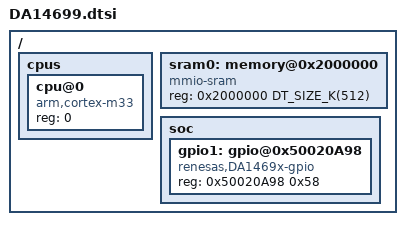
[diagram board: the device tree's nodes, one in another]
#include <dt-bindings/gpio/gpio.h>
#include <mem.h>

// sysclk: system-clock {
// 	compatible = "fixed-clock";
// 	clock-frequency = <25000000>;
// 	#clock-cells = <0>;
// };

/ {

	cpus {
		#address-cells = <1>;
		#size-cells = <0>;

		cpu@0 {
			device_type = "cpu";
			compatible = "arm,cortex-m33";
			reg = <0>;
			#address-cells = <1>;
			#size-cells = <1>;
		};
	};

	sram0: memory@0x2000000 {
		compatible = "mmio-sram";
		reg = <0x2000000 DT_SIZE_K(512)>; //TODO: leave space AREA_OVERHEAD
	};

	soc {
		gpio1: gpio@0x50020A98 {
			compatible = "renesas,DA1469x-gpio"
			gpio-controller;
			#gpio-cells = <2>; 
			reg = <0x50020A98 0x58>;
		};
	};
};
